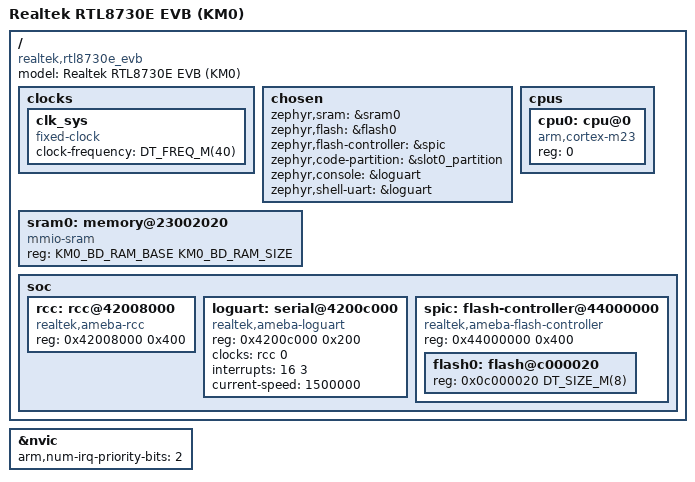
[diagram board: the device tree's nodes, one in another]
/*
 * Copyright (c) 2026 Realtek Semiconductor Corp.
 *
 * SPDX-License-Identifier: Apache-2.0
 *
 * KM0 (Cortex-M23) image2 runs from KM0_BD_RAM, loaded by the LP bootloader once KM4
 * releases KM0. flash0 is the KM0_IMG2_XIP window, for the flash driver and partitions only.
 */

/dts-v1/;

#include <arm/armv8-m.dtsi>
#include <mem.h>
#include <freq.h>
#include "rtl8730e_evb_partitions.h"

/* KM0_BD_RAM from project_lp ameba_layout.ld */
#define KM0_BD_RAM_BASE  0x23002020
#define KM0_BD_RAM_SIZE  (0x2301FD00 - 0x23002020)

/ {
	model = "Realtek RTL8730E EVB (KM0)";
	compatible = "realtek,rtl8730e_evb";

	clocks {
		/* bootloader_lp clocks KM0 from the 40 MHz XTAL */
		clk_sys: clk_sys {
			#clock-cells = <0>;
			compatible = "fixed-clock";
			clock-frequency = <DT_FREQ_M(40)>;
		};
	};

	chosen {
		zephyr,sram             = &sram0;
		zephyr,flash            = &flash0;
		zephyr,flash-controller = &spic;
		zephyr,code-partition   = &slot0_partition;
		zephyr,console          = &loguart;
		zephyr,shell-uart       = &loguart;
	};

	sram0: memory@23002020 {
		compatible = "mmio-sram";
		reg = <KM0_BD_RAM_BASE KM0_BD_RAM_SIZE>;
	};

	cpus {
		#address-cells = <1>;
		#size-cells = <0>;

		cpu0: cpu@0 {
			device_type = "cpu";
			compatible = "arm,cortex-m23";
			reg = <0>;
		};
	};

	soc {
		rcc: rcc@42008000 {
			compatible = "realtek,ameba-rcc";
			reg = <0x42008000 0x400>;
			#clock-cells = <1>;
			status = "okay";
		};

		/* Shared LOGUART. Its KM0 NVIC line is 16, not 8 as on KM4. */
		loguart: serial@4200c000 {
			compatible = "realtek,ameba-loguart";
			reg = <0x4200c000 0x200>;
			clocks = <&rcc 0>;
			interrupts = <16 3>;
			current-speed = <1500000>;
			status = "okay";
		};

		/* SPIC, KM0 XIP logic window (KM0_IMG2_XIP) */
		spic: flash-controller@44000000 {
			compatible = "realtek,ameba-flash-controller";
			reg = <0x44000000 0x400>;
			#address-cells = <1>;
			#size-cells = <1>;
			status = "okay";

			flash0: flash@c000020 {
				reg = <0x0c000020 DT_SIZE_M(8)>;
#include "rtl8730e_evb_partitions.dtsi"
			};
		};
	};
};

/* KM0 NVIC implements 2 priority bits */
&nvic {
	arm,num-irq-priority-bits = <2>;
};
